# STM32WL3R register map
File version: 1.0
CPU: CM0+ r0p0, little endian, MPU, no FPU, 4 interrupt priority bits
Registers are 32-bit, read-write, reset 0x0 unless marked. A register's access mark holds for its fields unless they carry their own. Offsets are from the block's base; [hi:lo] are bit positions.

## PWRC — PWRC address block description
Base 0x48500000
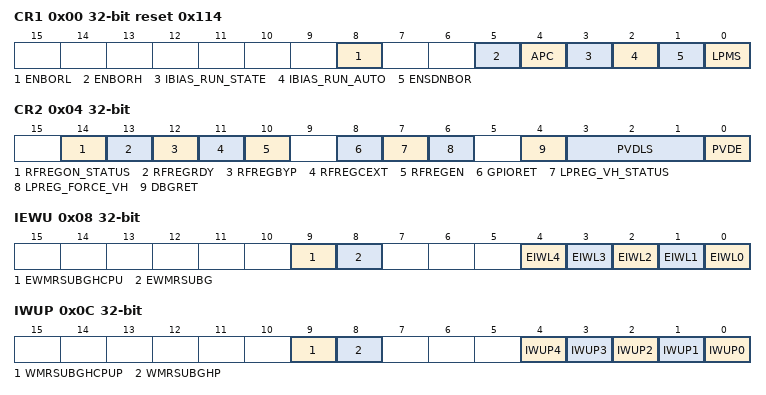
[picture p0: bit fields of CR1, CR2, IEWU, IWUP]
0x00 CR1 reset 0x114
  [8] ENBORL — ENBORL: Enable BORL reset supervising during RUN mode.
  [5] ENBORH — ENBORH: enable BORH configuration
  [4] APC — APC Apply Pull-up and pull-down configuration from CPU
  [3] IBIAS_RUN_STATE — IBIAS_RUN_STATE: Enable/Disable IBIAS during RUN mode when automatic mode is
  [2] IBIAS_RUN_AUTO — IBIAS_RUN_AUTO: Enable automatic IBIAS control during RUN/DEEPSTOP mode.
  [1] ENSDNBOR — ENSDNBOR: Enable BOR supply monitoring during shutdown mode.
  [0] LPMS — LPMS Low Power Mode Selection
0x04 CR2
  [14] RFREGON_STATUS ro — RFREGON_STATUS: RF Regulator On Status
  [13] RFREGRDY ro — RFDREGRDY: RF Regulator Ready flag
  [12] RFREGBYP — RFREGBYP: RF Regulator Bypass Enable
  [11] RFREGCEXT — RFREGCEXT: RF Regulator External Supply Bypass
  [10] RFREGEN — RFREGEN: RF Regulator Enable
  [8] GPIORET — GPIORET: GPIO retention enable.
  [7] LPREG_VH_STATUS ro — status LPREG VH (1.
  [6] LPREG_FORCE_VH — force LPREG=1.
  [4] DBGRET — DBGRET: PA2 and PA3 retention enable after DEEPSTOP
  [3:1] PVDLS — PVDLS[2:0] Programmable Voltage Detector Level selection
  [0] PVDE — PVDE Programmable Voltage Detector Enable
0x08 IEWU
  [9] EWMRSUBGHCPU — EWMRSUBGHCPU Wakeup MRSUBG Host CPU Enable
  [8] EWMRSUBG — EWMRSUB Wakeup MRSUBG Enable
  [4] EIWL4 — EIWL4 Enable Internal Wakeup line LCSC
  [3] EIWL3 — EIWL3 Enable Internal Wakeup line COMP
  [2] EIWL2 — EIWL2 Enable Internal WakeUp line LCD
  [1] EIWL1 — EIWL1 Enable Internal WakeUp line RTC
  [0] EIWL0 — EWL0 Enable Internal WakeUp line LPUART
0x0C IWUP
  [9] WMRSUBGHCPUP — WMRSUBGHCPUP: Wakeup polarity for internal wakeup MRSUBG Host CPU event
  [8] WMRSUBGHP — WMRSUBGHP: Wakeup polarity for internal wakeup MRSUBG event
  [4] IWUP4 — IWUP4: Wakeup polarity for internal wakeup line 4 event (LCSC).
  [3] IWUP3 — IWUP3: Wakeup polarity for internal wakeup line 3 event (COMP).
  [2] IWUP2 — IWUP2: Wakeup polarity for internal wakeup line 2 event (LCD).
  [1] IWUP1 — IWUP1: Wakeup polarity for internal wakeup line 1 event (RTC).
  [0] IWUP0 — IWUP0: Wakeup polarity for internal wakeup line 0 event (LPUART).
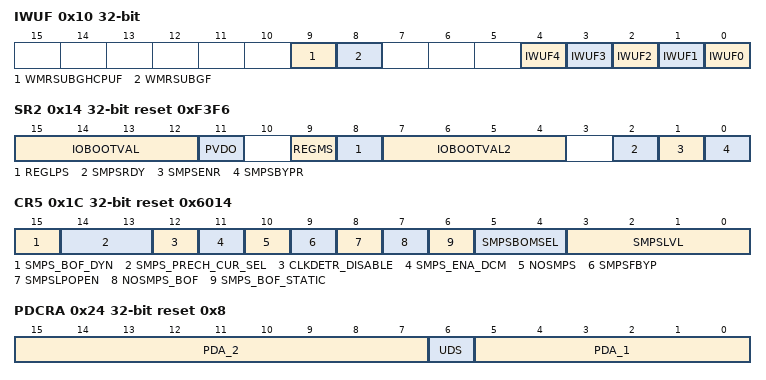
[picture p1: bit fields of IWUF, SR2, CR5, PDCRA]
0x10 IWUF
  [9] WMRSUBGHCPUF — WMRSUBGHCPUF Wakeup MRSUBG HOST CPU Flag (cf.
  [8] WMRSUBGF — WMRSUBGF Wakeup MRSUBG Flag
  [4] IWUF4 — IWUF4: Internal wakeup flag (LCSC).
  [3] IWUF3 — IWUF3: Internal wakeup flag (COMP).
  [2] IWUF2 — IWUF2: Internal wakeup flag (LCD).
  [1] IWUF1 — IWUF1: Internal wakeup flag (RTC).
  [0] IWUF0 — IWUF0: Internal wakeup flag (LPUART).
0x14 SR2 ro reset 0xF3F6
  [15:12] IOBOOTVAL — Bit3: PA11 input value on VDD33 latched at POR
  [11] PVDO — PVDO: Power Voltage Detector Output
  [9] REGMS — REGMS: Main regulator ready status.
  [8] REGLPS — REGLPS: Regulator Low Power Started
  [7:4] IOBOOTVAL2 — Bit3: PB15 input value on VDD33 latched at POR
  [2] SMPSRDY — SMPSRDY: SMPS Ready Status
  [1] SMPSENR — SMPSENR: SMPS Enable Control Replica
  [0] SMPSBYPR — SMPSBYPR: SMPS Force Bypass Control Replica
0x1C CR5 reset 0x6014
  [15] SMPS_BOF_DYN — SMPS_BOF_DYN: SMPS Bypass on the Fly dynamic
  [14:13] SMPS_PRECH_CUR_SEL — SMPS_PRECH_CUR_SEL[1:0] Selection for SMPS PRECHARGE limit current
  [12] CLKDETR_DISABLE — CLKDETR_DISABLE: disable SMPS clock detection
  [11] SMPS_ENA_DCM — SMPS_ENA_DCM: enable discontinuous conduction mode
  [10] NOSMPS — NOSMPS: No SMPS Mode
  [9] SMPSFBYP — SMPSFB Force SMPS Regulator in bypass mode
  [8] SMPSLPOPEN — SMPSLPOPEN: In Low Power mode SMPS is in OPEN mode (instead of PRECHARGE mode).
  [7] NOSMPS_BOF — NOSMPS_BOF: No SMPS Mode to be used in accordance to SMPS_BOF_STATIC =1
  [6] SMPS_BOF_STATIC — SMPS_BOF_STATIC: SMPS Bypass on the Fly static
  [5:4] SMPSBOMSEL — SMPSBOMSEL: SMPS BOM Selection:
  [3:0] SMPSLVL — SMPSLVL[3:0] SMPS Output Level Voltage Selection
0x20 PUCRA reset 0xFFF7
  [15:0] PUA — PUA[x] : Pull Up Port A
0x24 PDCRA reset 0x8
  [15:7] PDA_2 — PDA[x]: Pull Down Port A
  [6] UDS — UDS Ultra DeepStop Mode Selection
  [5:0] PDA_1 — PDA[x]: Pull Down Port A
0x28 PUCRB reset 0xFFFF
  [15:0] PUB — PUB[x] : Pull Up Port B
0x2C PDCRB
  [15:0] PDB — PDB[x]: Pull Down Port B
0x30 EWUA
  [15:0] EWUA — EWUA[x] Enable WakeUp line PA[x]
0x34 WUPA
  [15:0] WUPA — WUPA[x] Wake-up Line PA[x] Polarity
0x38 WUFA
  [15:0] WUFA — WUFA[x] WakeUp Flag PA[x]
0x40 EWUB
  [15:0] EWUB — EWUB[x] Enable WakeUp line PB[x]
0x44 WUPB
  [15:0] WUPB — WUPB[x] Wake-up Line PB[x] Polarity
0x48 WUFB
  [15:0] WUFB — WUFB[x] WakeUp Flag PB[x]
0x4C SDWN_WUEN
  [0] WUEN — WUEN PB0 I/O WakeUp from shutdown Enable
0x50 SDWN_WUPOL
  [0] WUPOL — WUPOL PB0 I/O WakeUp from shutdown Polarity
0x54 SDWN_WUF
  [0] WUF — WUF PB0 I/O WakeUp from shutdown Flag
0x58 BOF_TUNE reset 0x4
  [3:0] BOF_TUNE — BOF_TUNE: selection of the Bypass on the Fly LDO output voltage.
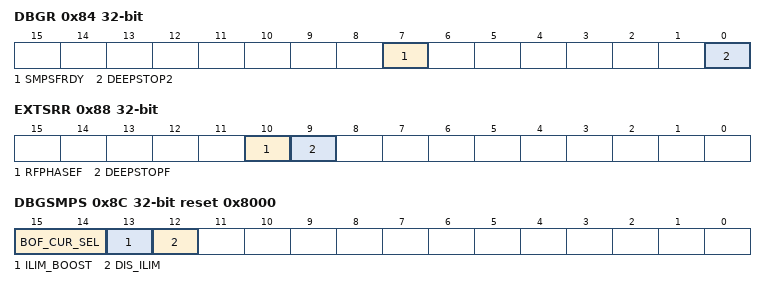
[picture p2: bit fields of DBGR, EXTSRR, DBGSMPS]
0x84 DBGR
  [7] SMPSFRDY — SMPSFB Force ready check
  [0] DEEPSTOP2 — DEEPSTOP2 low power saving mode emulation enable
0x88 EXTSRR
  [10] RFPHASEF — RFPHASEF RFPHASE Flag
  [9] DEEPSTOPF — DEEPSTOPF System DeepStop Flag
0x8C DBGSMPS reset 0x8000
  [15:14] BOF_CUR_SEL — BOF_CUR_SEL Bypass On the Fly current limitation
  [13] ILIM_BOOST — ILIM_BOOST_3V3 SMPS current limitation Boost
  [12] DIS_ILIM — DIS_ILIM_3V3 SMPS control signal
